# MDR1986VK214 register map
Vendor: Milandr; Series: ARMCM0; File version: 2.0
ARM 32-bit Cortex-M0 Microcontroller based device, CPU clock up to 36MHz, etc.
CPU: CM0 r0p0, little endian, no MPU, no FPU, 2 interrupt priority bits
Registers are 32-bit, read-write, reset 0x0 unless marked. A register's access mark holds for its fields unless they carry their own. Offsets are from the block's base; lines under a group give offsets from that group; [hi:lo] are bit positions; {n}, {i} and the like mark numbered series; 'fields as' and 'values as' point back to an identical list; <NAME> marks a mode.

## Memory map
0x40000000 MDR_SSP1 size 0x28 — Synchronous Serial Port
0x40008000 MDR_UART1 size 0x84 — UART Control
0x40010000 MDR_UART2 size 0x84
0x40018000 MDR_EEPROM size 0x14 — EEPROM Control
0x40020000 MDR_RST_CLOCK size 0x30 — CLock Control
0x40030000 MDR_I2C size 0x24 — I2C Controler
0x40038000 MDR_LCD_VK214 size 0x24 — LCD Display Controler
0x40040000 MDR_ADC size 0x34 — Successive Approximation ADC
0x40048000 MDR_WWDT size 0xC — Window Watchdog Timer
0x40050000 MDR_IWDT size 0x10 — Independent Watchdog Timer
0x40058000 MDR_Power size 0x8 — Power Detector
0x40060000 MDR_BKP size 0x54 — Backup and RTC Control
0x40068000 MDR_ADCUI size 0x124 — Energy Counter Block
0x40070000 MDR_TIMER1 size 0x80 — TIMER Control
0x40078000 MDR_TIMER2 size 0x80
0x40080000 MDR_PORTA size 0x2C — GPIO Port Control
0x40088000 MDR_PORTB size 0x2C
0x40090000 MDR_PORTC size 0x2C

## MDR_EEPROM — EEPROM Control
Base 0x40018000
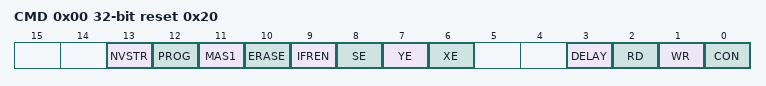
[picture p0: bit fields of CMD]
0x00 CMD reset 0x20 (reset mask 0x3FF) — EEPROM Control register
  [13] NVSTR — Memory access mode
    0=Read mode; 1=Write (Programming or erase mode)
  [12] PROG — Programm EEPROM_DI to ADDR[16:0]
    0=Inactive (No programm operation); 1=Active (Programm operation)
  [11] MAS1 — Erase whole block with ERASE
    0=Off (Disable); 1=On (Enable)
  [10] ERASE — Erase string at ADDR[16:0]
    0=Inactive (No erase operation); 1=Active (Erase operation)
  [9] IFREN — Select main or info memory
    0=Main memory; 1=Info memory
  [8] SE — RD Amplifier enable
    0=Off (Disable); 1=On (Enable)
  [7] YE — Enable ADDR[8..2]
    0=Off (Disable); 1=On (Enable)
  [6] XE — Enable ADDR[16..9]
    0=Off (Disable); 1=On (Enable)
  [3] DELAY — Memory access CPU delay tacts
    0=le18MHz (CPU freq is up to 18MHz); 1=le36MHz (CPU freq is up to 36MHz)
  [2] RD — Read operation, (test bit)
    0=Inactive (No read operation); 1=Active (Read operation)
  [1] WR — Write operation (test bit)
    0=Inactive (No write operation); 1=Active (Write operation)
  [0] CON — Enable memory access through EEPROM controller
    0=Normal access to memory; 1=Controller Access (Access to memory though registers)
0x04 ADDR — Address register
0x08 DI — Write data register
0x0C DO — Read data register
0x10 KEY — Unlock block register

## MDR_I2C — I2C Controler
Base 0x40030000
0x00 PRL — BitRate Div[7:0] of HCLK
  [7:0] PRL — Div[7:0] of HCLK
0x04 PRH — BitRate Div[15:8] of HCLK
  [7:0] PRH — Div[15:8] of HCLK
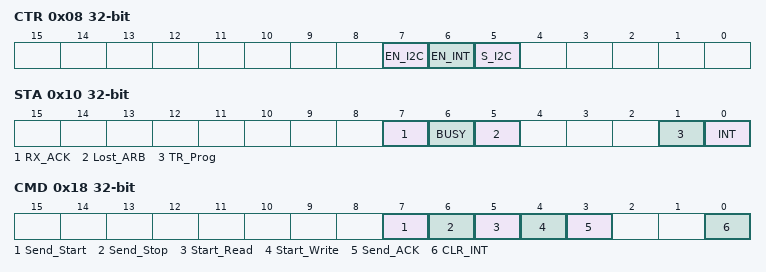
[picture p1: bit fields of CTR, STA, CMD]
0x08 CTR — Control Register
  [7] EN_I2C — Enable
    0=Off (Disabled); 1=On (Enabled)
  [6] EN_INT — Enable IRQ
    0=Off (Disabled); 1=On (Enabled)
  [5] S_I2C — Speed range of I2C
    0=less_400KHz (BitRate is less 400KHz); 1=less_1MHz (BitRate is less 1MHz)
0x0C RXD — Received Data
  [7:0] DATA — Received Byte
0x10 STA — Status register
  [7] RX_ACK — ACK Status
    0=Ok (Acknowledge received); 1=No Acknowledge received
  [6] BUSY — Line Busy
    0=Bus_Free (Stop received); 1=Bus_Busy (Start received)
  [5] Lost_ARB — Lost arbitrage
    0=Ok (Normal operation); 1=Collision detected
  [1] TR_Prog — Transfering status
    0=Completed (Transfering is completed); 1=Transfering is not completed
  [0] INT — IRQ Event Flag
    0=Off (Inactive); 1=On (Active)
0x14 TXD — Data to Send
  [7:0] DATA — Send Byte
0x18 CMD — Command Register
  [7] Send_Start — Send Start command
    0=Inactive state; 1=Send Start command
  [6] Send_Stop — Send Stop command
    0=Inactive state; 1=Send Stop command
  [5] Start_Read — Start Reading transfer
    0=Inactive state; 1=Start reading
  [4] Start_Write — Start Writing transfer
    0=Inactive state; 1=Start_Write (Start writing)
  [3] Send_ACK — Send ACK command
    0=Inactive state; 1=Send Ack command
  [0] CLR_INT — Clear IRQ Event
    0=Inactive state; 1=Clear IRQ flag
